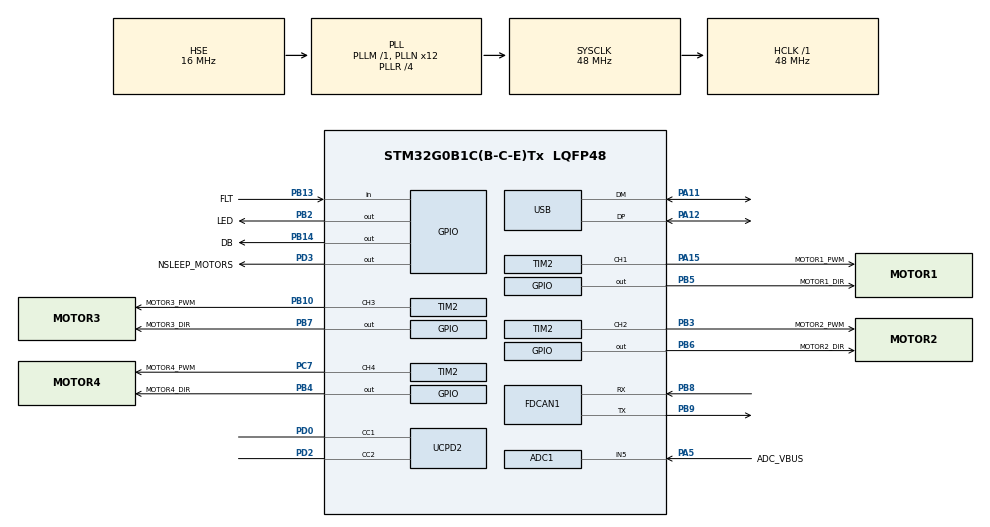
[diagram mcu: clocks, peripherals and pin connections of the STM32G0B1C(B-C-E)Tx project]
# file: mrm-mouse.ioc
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ADC1.Channel-1\#ChannelRegularConversion=ADC_CHANNEL_5
ADC1.NbrOfConversionFlag=1
ADC1.Rank-1\#ChannelRegularConversion=1
ADC1.SamplingTime-1\#ChannelRegularConversion=ADC_SAMPLINGTIME_COMMON_1
ADC1.SamplingTimeCommon1=ADC_SAMPLETIME_160CYCLES_5
ADC1.SelectedChannel=ADC_CHANNEL_5
ADC1.master=1
Dma.Request0=UCPD2_RX
Dma.Request1=UCPD2_TX
Dma.UCPD2_RX.0.Direction=DMA_PERIPH_TO_MEMORY
Dma.UCPD2_RX.0.EventEnable=DISABLE
Dma.UCPD2_RX.0.Instance=DMA1_Channel1
Dma.UCPD2_RX.0.MemDataAlignment=DMA_MDATAALIGN_BYTE
Dma.UCPD2_RX.0.MemInc=DMA_MINC_ENABLE
Dma.UCPD2_RX.0.Mode=DMA_NORMAL
Dma.UCPD2_RX.0.PeriphDataAlignment=DMA_PDATAALIGN_BYTE
Dma.UCPD2_RX.0.PeriphInc=DMA_PINC_DISABLE
Dma.UCPD2_RX.0.Polarity=HAL_DMAMUX_REQ_GEN_RISING
Dma.UCPD2_RX.0.Priority=DMA_PRIORITY_LOW
Dma.UCPD2_RX.0.RequestNumber=1
Dma.UCPD2_RX.0.SignalID=NONE
Dma.UCPD2_RX.0.SyncEnable=DISABLE
Dma.UCPD2_RX.0.SyncPolarity=HAL_DMAMUX_SYNC_NO_EVENT
Dma.UCPD2_RX.0.SyncRequestNumber=1
Dma.UCPD2_RX.0.SyncSignalID=NONE
Dma.UCPD2_TX.1.Direction=DMA_MEMORY_TO_PERIPH
Dma.UCPD2_TX.1.EventEnable=DISABLE
Dma.UCPD2_TX.1.Instance=DMA1_Channel2
Dma.UCPD2_TX.1.MemDataAlignment=DMA_MDATAALIGN_BYTE
Dma.UCPD2_TX.1.MemInc=DMA_MINC_ENABLE
Dma.UCPD2_TX.1.Mode=DMA_NORMAL
Dma.UCPD2_TX.1.PeriphDataAlignment=DMA_PDATAALIGN_BYTE
Dma.UCPD2_TX.1.PeriphInc=DMA_PINC_DISABLE
Dma.UCPD2_TX.1.Polarity=HAL_DMAMUX_REQ_GEN_RISING
Dma.UCPD2_TX.1.Priority=DMA_PRIORITY_LOW
Dma.UCPD2_TX.1.RequestNumber=1
Dma.UCPD2_TX.1.SignalID=NONE
Dma.UCPD2_TX.1.SyncEnable=DISABLE
Dma.UCPD2_TX.1.SyncPolarity=HAL_DMAMUX_SYNC_NO_EVENT
Dma.UCPD2_TX.1.SyncRequestNumber=1
Dma.UCPD2_TX.1.SyncSignalID=NONE
FDCAN1.AutoRetransmission=ENABLE
FDCAN1.CalculateBaudRateNominal=250000
FDCAN1.CalculateTimeBitNominal=4000
FDCAN1.CalculateTimeQuantumNominal=250.0
FDCAN1.NominalPrescaler=12
FDCAN1.NominalSyncJumpWidth=2
FDCAN1.NominalTimeSeg1=13
FDCAN1.NominalTimeSeg2=2
Mcu.Family=STM32G0
Mcu.Name=STM32G0B1C(B-C-E)Tx
Mcu.Package=LQFP48
NVIC.DMA1_Channel1_IRQn=true\:0\:0\:false\:false\:true\:false\:true\:true
NVIC.DMA1_Channel2_3_IRQn=true\:0\:0\:false\:false\:true\:false\:true\:true
NVIC.TIM16_FDCAN_IT0_IRQn=true\:0\:0\:false\:false\:true\:true\:true\:true
NVIC.USB_UCPD1_2_IRQn=true\:0\:0\:false\:false\:true\:true\:true\:true
PA11\ [PA9].Mode=Device
PA11\ [PA9].Signal=USB_DM
PA12\ [PA10].Mode=Device
PA12\ [PA10].Signal=USB_DP
PA13.Mode=Serial_Wire
PA13.Signal=SYS_SWDIO
PA14-BOOT0.Mode=Serial_Wire
PA14-BOOT0.Signal=SYS_SWCLK
PA15.GPIO_Label=MOTOR1_PWM
PA15.Signal=S_TIM2_CH1_ETR
PA5.GPIO_Label=ADC_VBUS
PA5.Mode=IN5
PA5.Signal=ADC1_IN5
PB10.GPIO_Label=MOTOR3_PWM
PB10.Signal=S_TIM2_CH3
PB13.GPIO_Label=FLT
PB13.Signal=GPIO_Input
PB14.GPIO_Label=DB
PB14.Signal=GPIO_Output
PB2.GPIO_Label=LED
PB2.Signal=GPIO_Output
PB3.GPIO_Label=MOTOR2_PWM
PB3.Signal=S_TIM2_CH2
PB4.GPIO_Label=MOTOR4_DIR
PB4.Signal=GPIO_Output
PB5.GPIO_Label=MOTOR1_DIR
PB5.Signal=GPIO_Output
PB6.GPIO_Label=MOTOR2_DIR
PB6.Signal=GPIO_Output
PB7.GPIO_Label=MOTOR3_DIR
PB7.Signal=GPIO_Output
PB8.Mode=FDCAN_Activate
PB8.Signal=FDCAN1_RX
PB9.Mode=FDCAN_Activate
PB9.Signal=FDCAN1_TX
PC7.GPIO_Label=MOTOR4_PWM
PC7.Signal=S_TIM2_CH4
PD0.Mode=Sink_AllSignals
PD0.Signal=UCPD2_CC1
PD2.Mode=Sink_AllSignals
PD2.Signal=UCPD2_CC2
PD3.GPIO_Label=NSLEEP_MOTORS
PD3.Signal=GPIO_Output
PF0-OSC_IN\ (PF0).Mode=HSE-External-Oscillator
PF0-OSC_IN\ (PF0).Signal=RCC_OSC_IN
PF1-OSC_OUT\ (PF1).Mode=HSE-External-Oscillator
PF1-OSC_OUT\ (PF1).Signal=RCC_OSC_OUT
ProjectManager.HeapSize=0x200
ProjectManager.StackSize=0x400
ProjectManager.TargetToolchain=CMake
RCC.ADCFreq_Value=48000000
RCC.AHBFreq_Value=48000000
RCC.CortexFreq_Value=48000000
RCC.EXTERNAL_CLOCK_VALUE=48000
RCC.HCLKFreq_Value=48000000
RCC.HSE_VALUE=16000000
RCC.HSI48_VALUE=48000000
RCC.HSI_VALUE=16000000
RCC.LSE_VALUE=32768
RCC.PLLN=12
RCC.PLLR=RCC_PLLR_DIV4
RCC.PLLSourceVirtual=RCC_PLLSOURCE_HSE
RCC.SYSCLKFreq_VALUE=48000000
RCC.SYSCLKSource=RCC_SYSCLKSOURCE_PLLCLK
RCC.USBFreq_Value=48000000
RCC.VCOOutputFreq_Value=192000000
SH.S_TIM2_CH1_ETR.0=TIM2_CH1,PWM Generation1 CH1
SH.S_TIM2_CH2.0=TIM2_CH2,PWM Generation2 CH2
SH.S_TIM2_CH3.0=TIM2_CH3,PWM Generation3 CH3
SH.S_TIM2_CH4.0=TIM2_CH4,PWM Generation4 CH4
TIM2.Channel-PWM\ Generation1\ CH1=TIM_CHANNEL_1
TIM2.Channel-PWM\ Generation2\ CH2=TIM_CHANNEL_2
TIM2.Channel-PWM\ Generation3\ CH3=TIM_CHANNEL_3
TIM2.Channel-PWM\ Generation4\ CH4=TIM_CHANNEL_4
TIM2.OCPolarity_1=TIM_OCPOLARITY_LOW
TIM2.OCPolarity_2=TIM_OCPOLARITY_LOW
TIM2.OCPolarity_3=TIM_OCPOLARITY_LOW
TIM2.OCPolarity_4=TIM_OCPOLARITY_LOW
TIM2.Period=99
TIM2.Prescaler=47
USB_DEVICE.CLASS_NAME_FS=CDC
USB_DEVICE.VirtualMode=Cdc
USB_DEVICE.VirtualModeFS=Cdc_FS
VP_SYS_VS_DBSignals.Mode=DisableDeadBatterySignals
VP_USBPD_VS_PD3FULL.Mode=PD3_Full_Stack
VP_USBPD_VS_USBPD2.Mode=USBPD_P0
VP_USBPD_VS_usbpd_tim3.Mode=TIM3
VP_USBPD_VS_usbpd_usb_cohabitation.Mode=Enable USB Support
VP_USB_DEVICE_VS_USB_DEVICE_CDC_FS.Mode=CDC_FS
board=custom

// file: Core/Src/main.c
/* USER CODE BEGIN Header */
/**
  ******************************************************************************
  * @file           : main.c
  * @brief          : Main program body
  ******************************************************************************
  * @attention
  *
  * Copyright (c) 2026 STMicroelectronics.
  * All rights reserved.
  *
  * This software is licensed under terms that can be found in the LICENSE file
  * in the root directory of this software component.
  * If no LICENSE file comes with this software, it is provided AS-IS.
  *
  ******************************************************************************
  */
/* USER CODE END Header */
#include "main.h"
#include "usbpd.h"
#include "usb_device.h"

/* USER CODE BEGIN Includes */
#include "app_usb_bridge.h"
#include "can_bus.h"
#include "motor_control.h"
#include "usb_commands.h"
/* USER CODE END Includes */

ADC_HandleTypeDef hadc1;

FDCAN_HandleTypeDef hfdcan1;

TIM_HandleTypeDef htim2;

void SystemClock_Config(void);
static void MX_GPIO_Init(void);
static void MX_DMA_Init(void);
static void MX_FDCAN1_Init(void);
static void MX_TIM2_Init(void);
static void MX_UCPD2_Init(void);
static void MX_ADC1_Init(void);

int main(void)
{

  /* MCU Configuration--------------------------------------------------------*/

  /* Reset of all peripherals, Initializes the Flash interface and the Systick. */
  HAL_Init();

  /* Configure the system clock */
  SystemClock_Config();

  /* Initialize all configured peripherals */
  MX_GPIO_Init();
  MX_DMA_Init();
  MX_FDCAN1_Init();
  MX_TIM2_Init();
  MX_UCPD2_Init();
  MX_ADC1_Init();
  MX_USB_Device_Init();
  /* USER CODE BEGIN 2 */
  AppUsbBridge_Init();
  UsbCommands_SetPollFunction(USBPD_DPM_Poll);
  if (CanBus_Init() != HAL_OK)
  {
    Error_Handler();
  }
  /* USER CODE END 2 */

  /* USBPD initialisation ---------------------------------*/
  MX_USBPD_Init();

  /* Infinite loop */
  while (1)
  {
    USBPD_DPM_Run();

  }
}

void SystemClock_Config(void)
{
  RCC_OscInitTypeDef RCC_OscInitStruct = {0};
  RCC_ClkInitTypeDef RCC_ClkInitStruct = {0};

  /** Configure the main internal regulator output voltage
  */
  HAL_PWREx_ControlVoltageScaling(PWR_REGULATOR_VOLTAGE_SCALE1);

  /** Initializes the RCC Oscillators according to the specified parameters
  * in the RCC_OscInitTypeDef structure.
  */
  RCC_OscInitStruct.OscillatorType = RCC_OSCILLATORTYPE_HSI|RCC_OSCILLATORTYPE_HSE
                              |RCC_OSCILLATORTYPE_HSI48;
  RCC_OscInitStruct.HSEState = RCC_HSE_ON;
  RCC_OscInitStruct.HSIState = RCC_HSI_ON;
  RCC_OscInitStruct.HSI48State = RCC_HSI48_ON;
  RCC_OscInitStruct.HSIDiv = RCC_HSI_DIV1;
  RCC_OscInitStruct.HSICalibrationValue = RCC_HSICALIBRATION_DEFAULT;
  RCC_OscInitStruct.PLL.PLLState = RCC_PLL_ON;
  RCC_OscInitStruct.PLL.PLLSource = RCC_PLLSOURCE_HSE;
  RCC_OscInitStruct.PLL.PLLM = RCC_PLLM_DIV1;
  RCC_OscInitStruct.PLL.PLLN = 12;
  RCC_OscInitStruct.PLL.PLLP = RCC_PLLP_DIV2;
  RCC_OscInitStruct.PLL.PLLQ = RCC_PLLQ_DIV2;
  RCC_OscInitStruct.PLL.PLLR = RCC_PLLR_DIV4;
  if (HAL_RCC_OscConfig(&RCC_OscInitStruct) != HAL_OK)
  {
    Error_Handler();
  }

  /** Initializes the CPU, AHB and APB buses clocks
  */
  RCC_ClkInitStruct.ClockType = RCC_CLOCKTYPE_HCLK|RCC_CLOCKTYPE_SYSCLK
                              |RCC_CLOCKTYPE_PCLK1;
  RCC_ClkInitStruct.SYSCLKSource = RCC_SYSCLKSOURCE_PLLCLK;
  RCC_ClkInitStruct.AHBCLKDivider = RCC_SYSCLK_DIV1;
  RCC_ClkInitStruct.APB1CLKDivider = RCC_HCLK_DIV1;

  if (HAL_RCC_ClockConfig(&RCC_ClkInitStruct, FLASH_LATENCY_1) != HAL_OK)
  {
    Error_Handler();
  }
}

static void MX_ADC1_Init(void)
{

  ADC_ChannelConfTypeDef sConfig = {0};

  /** Configure the global features of the ADC (Clock, Resolution, Data Alignment and number of conversion)
  */
  hadc1.Instance = ADC1;
  hadc1.Init.ClockPrescaler = ADC_CLOCK_SYNC_PCLK_DIV2;
  hadc1.Init.Resolution = ADC_RESOLUTION_12B;
  hadc1.Init.DataAlign = ADC_DATAALIGN_RIGHT;
  hadc1.Init.ScanConvMode = ADC_SCAN_DISABLE;
  hadc1.Init.EOCSelection = ADC_EOC_SINGLE_CONV;
  hadc1.Init.LowPowerAutoWait = DISABLE;
  hadc1.Init.LowPowerAutoPowerOff = DISABLE;
  hadc1.Init.ContinuousConvMode = DISABLE;
  hadc1.Init.NbrOfConversion = 1;
  hadc1.Init.DiscontinuousConvMode = DISABLE;
  hadc1.Init.ExternalTrigConv = ADC_SOFTWARE_START;
  hadc1.Init.ExternalTrigConvEdge = ADC_EXTERNALTRIGCONVEDGE_NONE;
  hadc1.Init.DMAContinuousRequests = DISABLE;
  hadc1.Init.Overrun = ADC_OVR_DATA_PRESERVED;
  hadc1.Init.SamplingTimeCommon1 = ADC_SAMPLETIME_160CYCLES_5;
  hadc1.Init.SamplingTimeCommon2 = ADC_SAMPLETIME_1CYCLE_5;
  hadc1.Init.OversamplingMode = DISABLE;
  hadc1.Init.TriggerFrequencyMode = ADC_TRIGGER_FREQ_HIGH;
  if (HAL_ADC_Init(&hadc1) != HAL_OK)
  {
    Error_Handler();
  }

  /** Configure Regular Channel
  */
  sConfig.Channel = ADC_CHANNEL_5;
  sConfig.Rank = ADC_REGULAR_RANK_1;
  sConfig.SamplingTime = ADC_SAMPLINGTIME_COMMON_1;
  if (HAL_ADC_ConfigChannel(&hadc1, &sConfig) != HAL_OK)
  {
    Error_Handler();
  }
  /* USER CODE BEGIN ADC1_Init 2 */
  if (HAL_ADCEx_Calibration_Start(&hadc1) != HAL_OK)
  {
    Error_Handler();
  }
  /* Keep the internal reference enabled and allow it to settle before PD
     starts sampling VBUS. Its factory calibration compensates VDDA drift. */
  LL_ADC_SetCommonPathInternalCh(__LL_ADC_COMMON_INSTANCE(ADC1),
                                LL_ADC_PATH_INTERNAL_VREFINT);
  HAL_Delay(1U);
  /* USER CODE END ADC1_Init 2 */

}

static void MX_FDCAN1_Init(void)
{

  hfdcan1.Instance = FDCAN1;
  hfdcan1.Init.ClockDivider = FDCAN_CLOCK_DIV1;
  hfdcan1.Init.FrameFormat = FDCAN_FRAME_CLASSIC;
  hfdcan1.Init.Mode = FDCAN_MODE_NORMAL;
  hfdcan1.Init.AutoRetransmission = ENABLE;
  hfdcan1.Init.TransmitPause = DISABLE;
  hfdcan1.Init.ProtocolException = DISABLE;
  hfdcan1.Init.NominalPrescaler = 12;
  hfdcan1.Init.NominalSyncJumpWidth = 2;
  hfdcan1.Init.NominalTimeSeg1 = 13;
  hfdcan1.Init.NominalTimeSeg2 = 2;
  hfdcan1.Init.DataPrescaler = 1;
  hfdcan1.Init.DataSyncJumpWidth = 1;
  hfdcan1.Init.DataTimeSeg1 = 1;
  hfdcan1.Init.DataTimeSeg2 = 1;
  hfdcan1.Init.StdFiltersNbr = 0;
  hfdcan1.Init.ExtFiltersNbr = 0;
  hfdcan1.Init.TxFifoQueueMode = FDCAN_TX_FIFO_OPERATION;
  if (HAL_FDCAN_Init(&hfdcan1) != HAL_OK)
  {
    Error_Handler();
  }

}

static void MX_TIM2_Init(void)
{

  TIM_MasterConfigTypeDef sMasterConfig = {0};
  TIM_OC_InitTypeDef sConfigOC = {0};

  htim2.Instance = TIM2;
  htim2.Init.Prescaler = 47;
  htim2.Init.CounterMode = TIM_COUNTERMODE_UP;
  htim2.Init.Period = 99;
  htim2.Init.ClockDivision = TIM_CLOCKDIVISION_DIV1;
  htim2.Init.AutoReloadPreload = TIM_AUTORELOAD_PRELOAD_DISABLE;
  if (HAL_TIM_PWM_Init(&htim2) != HAL_OK)
  {
    Error_Handler();
  }
  sMasterConfig.MasterOutputTrigger = TIM_TRGO_RESET;
  sMasterConfig.MasterSlaveMode = TIM_MASTERSLAVEMODE_DISABLE;
  if (HAL_TIMEx_MasterConfigSynchronization(&htim2, &sMasterConfig) != HAL_OK)
  {
    Error_Handler();
  }
  sConfigOC.OCMode = TIM_OCMODE_PWM1;
  sConfigOC.Pulse = 0;
  sConfigOC.OCPolarity = TIM_OCPOLARITY_LOW;
  sConfigOC.OCFastMode = TIM_OCFAST_DISABLE;
  if (HAL_TIM_PWM_ConfigChannel(&htim2, &sConfigOC, TIM_CHANNEL_1) != HAL_OK)
  {
    Error_Handler();
  }
  if (HAL_TIM_PWM_ConfigChannel(&htim2, &sConfigOC, TIM_CHANNEL_2) != HAL_OK)
  {
    Error_Handler();
  }
  if (HAL_TIM_PWM_ConfigChannel(&htim2, &sConfigOC, TIM_CHANNEL_3) != HAL_OK)
  {
    Error_Handler();
  }
  if (HAL_TIM_PWM_ConfigChannel(&htim2, &sConfigOC, TIM_CHANNEL_4) != HAL_OK)
  {
    Error_Handler();
  }
  HAL_TIM_MspPostInit(&htim2);

}

static void MX_UCPD2_Init(void)
{

  LL_GPIO_InitTypeDef GPIO_InitStruct = {0};

  /* Peripheral clock enable */
  LL_APB1_GRP1_EnableClock(LL_APB1_GRP1_PERIPH_UCPD2);

  LL_IOP_GRP1_EnableClock(LL_IOP_GRP1_PERIPH_GPIOD);
  /**UCPD2 GPIO Configuration
  PD0   ------> UCPD2_CC1
  PD2   ------> UCPD2_CC2
  */
  GPIO_InitStruct.Pin = LL_GPIO_PIN_0;
  GPIO_InitStruct.Mode = LL_GPIO_MODE_ANALOG;
  GPIO_InitStruct.Pull = LL_GPIO_PULL_NO;
  LL_GPIO_Init(GPIOD, &GPIO_InitStruct);

  GPIO_InitStruct.Pin = LL_GPIO_PIN_2;
  GPIO_InitStruct.Mode = LL_GPIO_MODE_ANALOG;
  GPIO_InitStruct.Pull = LL_GPIO_PULL_NO;
  LL_GPIO_Init(GPIOD, &GPIO_InitStruct);

  /* UCPD2 DMA Init */

  /* UCPD2_RX Init */
  LL_DMA_SetPeriphRequest(DMA1, LL_DMA_CHANNEL_1, LL_DMAMUX_REQ_UCPD2_RX);

  LL_DMA_SetDataTransferDirection(DMA1, LL_DMA_CHANNEL_1, LL_DMA_DIRECTION_PERIPH_TO_MEMORY);

  LL_DMA_SetChannelPriorityLevel(DMA1, LL_DMA_CHANNEL_1, LL_DMA_PRIORITY_LOW);

  LL_DMA_SetMode(DMA1, LL_DMA_CHANNEL_1, LL_DMA_MODE_NORMAL);

  LL_DMA_SetPeriphIncMode(DMA1, LL_DMA_CHANNEL_1, LL_DMA_PERIPH_NOINCREMENT);

  LL_DMA_SetMemoryIncMode(DMA1, LL_DMA_CHANNEL_1, LL_DMA_MEMORY_INCREMENT);

  LL_DMA_SetPeriphSize(DMA1, LL_DMA_CHANNEL_1, LL_DMA_PDATAALIGN_BYTE);

  LL_DMA_SetMemorySize(DMA1, LL_DMA_CHANNEL_1, LL_DMA_MDATAALIGN_BYTE);

  /* UCPD2_TX Init */
  LL_DMA_SetPeriphRequest(DMA1, LL_DMA_CHANNEL_2, LL_DMAMUX_REQ_UCPD2_TX);

  LL_DMA_SetDataTransferDirection(DMA1, LL_DMA_CHANNEL_2, LL_DMA_DIRECTION_MEMORY_TO_PERIPH);

  LL_DMA_SetChannelPriorityLevel(DMA1, LL_DMA_CHANNEL_2, LL_DMA_PRIORITY_LOW);

  LL_DMA_SetMode(DMA1, LL_DMA_CHANNEL_2, LL_DMA_MODE_NORMAL);

  LL_DMA_SetPeriphIncMode(DMA1, LL_DMA_CHANNEL_2, LL_DMA_PERIPH_NOINCREMENT);

  LL_DMA_SetMemoryIncMode(DMA1, LL_DMA_CHANNEL_2, LL_DMA_MEMORY_INCREMENT);

  LL_DMA_SetPeriphSize(DMA1, LL_DMA_CHANNEL_2, LL_DMA_PDATAALIGN_BYTE);

  LL_DMA_SetMemorySize(DMA1, LL_DMA_CHANNEL_2, LL_DMA_MDATAALIGN_BYTE);

  /* UCPD2 interrupt Init */
  NVIC_SetPriority(USB_UCPD1_2_IRQn, 0);
  NVIC_EnableIRQ(USB_UCPD1_2_IRQn);

}

static void MX_DMA_Init(void)
{

  /* DMA controller clock enable */
  __HAL_RCC_DMA1_CLK_ENABLE();

  /* DMA interrupt init */
  /* DMA1_Channel1_IRQn interrupt configuration */
  NVIC_SetPriority(DMA1_Channel1_IRQn, 0);
  NVIC_EnableIRQ(DMA1_Channel1_IRQn);
  /* DMA1_Channel2_3_IRQn interrupt configuration */
  NVIC_SetPriority(DMA1_Channel2_3_IRQn, 0);
  NVIC_EnableIRQ(DMA1_Channel2_3_IRQn);

}

static void MX_GPIO_Init(void)
{
  GPIO_InitTypeDef GPIO_InitStruct = {0};

  /* GPIO Ports Clock Enable */
  __HAL_RCC_GPIOF_CLK_ENABLE();
  __HAL_RCC_GPIOA_CLK_ENABLE();
  __HAL_RCC_GPIOB_CLK_ENABLE();
  __HAL_RCC_GPIOC_CLK_ENABLE();
  __HAL_RCC_GPIOD_CLK_ENABLE();

  /*Configure GPIO pin Output Level */
  HAL_GPIO_WritePin(GPIOB, LED_Pin|DB_Pin|MOTOR4_DIR_Pin|MOTOR1_DIR_Pin
                          |MOTOR2_DIR_Pin|MOTOR3_DIR_Pin, GPIO_PIN_RESET);

  /*Configure GPIO pin Output Level */
  HAL_GPIO_WritePin(NSLEEP_MOTORS_GPIO_Port, NSLEEP_MOTORS_Pin, GPIO_PIN_RESET);

  /*Configure GPIO pins : LED_Pin DB_Pin MOTOR4_DIR_Pin MOTOR1_DIR_Pin
                           MOTOR2_DIR_Pin MOTOR3_DIR_Pin */
  GPIO_InitStruct.Pin = LED_Pin|DB_Pin|MOTOR4_DIR_Pin|MOTOR1_DIR_Pin
                          |MOTOR2_DIR_Pin|MOTOR3_DIR_Pin;
  GPIO_InitStruct.Mode = GPIO_MODE_OUTPUT_PP;
  GPIO_InitStruct.Pull = GPIO_NOPULL;
  GPIO_InitStruct.Speed = GPIO_SPEED_FREQ_LOW;
  HAL_GPIO_Init(GPIOB, &GPIO_InitStruct);

  /*Configure GPIO pin : FLT_Pin */
  GPIO_InitStruct.Pin = FLT_Pin;
  GPIO_InitStruct.Mode = GPIO_MODE_INPUT;
  GPIO_InitStruct.Pull = GPIO_NOPULL;
  HAL_GPIO_Init(FLT_GPIO_Port, &GPIO_InitStruct);

  /*Configure GPIO pin : NSLEEP_MOTORS_Pin */
  GPIO_InitStruct.Pin = NSLEEP_MOTORS_Pin;
  GPIO_InitStruct.Mode = GPIO_MODE_OUTPUT_PP;
  GPIO_InitStruct.Pull = GPIO_NOPULL;
  GPIO_InitStruct.Speed = GPIO_SPEED_FREQ_LOW;
  HAL_GPIO_Init(NSLEEP_MOTORS_GPIO_Port, &GPIO_InitStruct);

}

void Error_Handler(void)
{
  __disable_irq();
  while (1)
  {
  }
}
